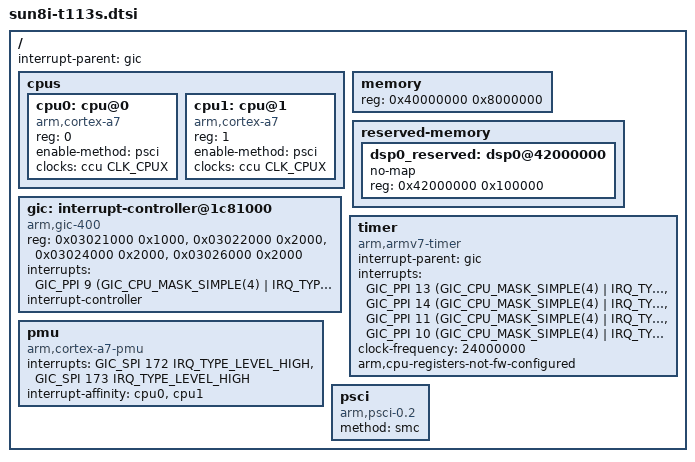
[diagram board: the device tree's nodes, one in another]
// SPDX-License-Identifier: (GPL-2.0+ OR MIT)
// Copyright (C) 2022 Arm Ltd.

#define SOC_PERIPHERAL_IRQ(nr) GIC_SPI nr

#include <dt-bindings/interrupt-controller/arm-gic.h>
#include <riscv/allwinner/sunxi-d1s-t113.dtsi>
#include <riscv/allwinner/sunxi-d1-t113.dtsi>

/ {
	interrupt-parent = <&gic>;

	cpus {
		#address-cells = <1>;
		#size-cells = <0>;

		cpu0: cpu@0 {
			compatible = "arm,cortex-a7";
			device_type = "cpu";
			reg = <0>;
			enable-method = "psci";
			clocks = <&ccu CLK_CPUX>;
			clock-names = "cpu";
		};

		cpu1: cpu@1 {
			compatible = "arm,cortex-a7";
			device_type = "cpu";
			reg = <1>;
			enable-method = "psci";
			clocks = <&ccu CLK_CPUX>;
			clock-names = "cpu";
		};
	};

	memory {
	    reg = <0x40000000 0x8000000>;
	};

	reserved-memory {
		#address-cells = <1>;
		#size-cells = <1>;
		ranges;

		dsp0_reserved: dsp0@42000000 {
			no-map;
			reg = <0x42000000 0x100000>;
		};
	};

	gic: interrupt-controller@1c81000 {
		compatible = "arm,gic-400";
		reg = <0x03021000 0x1000>,
		      <0x03022000 0x2000>,
		      <0x03024000 0x2000>,
		      <0x03026000 0x2000>;
		interrupts = <GIC_PPI 9 (GIC_CPU_MASK_SIMPLE(4) | IRQ_TYPE_LEVEL_HIGH)>;
		interrupt-controller;
		#interrupt-cells = <3>;
	};

	timer {
		compatible = "arm,armv7-timer";
		interrupt-parent = <&gic>;
		interrupts = <GIC_PPI 13 (GIC_CPU_MASK_SIMPLE(4) | IRQ_TYPE_LEVEL_LOW)>,
			     <GIC_PPI 14 (GIC_CPU_MASK_SIMPLE(4) | IRQ_TYPE_LEVEL_LOW)>,
			     <GIC_PPI 11 (GIC_CPU_MASK_SIMPLE(4) | IRQ_TYPE_LEVEL_LOW)>,
			     <GIC_PPI 10 (GIC_CPU_MASK_SIMPLE(4) | IRQ_TYPE_LEVEL_LOW)>;
		clock-frequency = <24000000>;
		arm,cpu-registers-not-fw-configured;
	};

	pmu {
		compatible = "arm,cortex-a7-pmu";
		interrupts = <GIC_SPI 172 IRQ_TYPE_LEVEL_HIGH>,
			     <GIC_SPI 173 IRQ_TYPE_LEVEL_HIGH>;
		interrupt-affinity = <&cpu0>, <&cpu1>;
	};

	psci {
		compatible = "arm,psci-0.2";
		method = "smc";
	};
};
